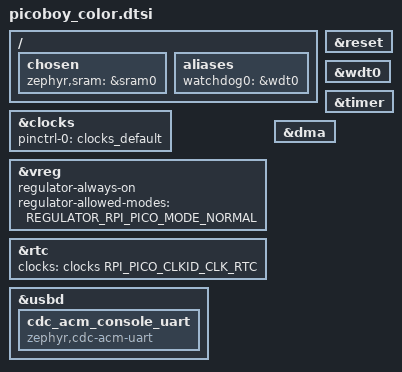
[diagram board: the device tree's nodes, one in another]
/*
 * Copyright (c) 2023-2025 TiaC Systems
 * SPDX-License-Identifier: Apache-2.0
 */

#include <mem.h>
#include <freq.h>
#include <raspberrypi/rpi_pico/rp2040.dtsi>
#include <zephyr/dt-bindings/regulator/rpi_pico.h>

#include "pbc-pinctrl.dtsi"

/ {
	chosen {
		zephyr,sram = &sram0;
	};

	aliases {
		watchdog0 = &wdt0;
	};
};

&clocks {
	pinctrl-0 = <&clocks_default>;
	pinctrl-names = "default";
};

&reset {
	status = "okay";
};

&vreg {
	regulator-always-on;
	regulator-allowed-modes = <REGULATOR_RPI_PICO_MODE_NORMAL>;
};

&wdt0 {
	status = "okay";
};

&rtc {
	clocks = <&clocks RPI_PICO_CLKID_CLK_RTC>;
	status = "okay";
};

&timer {
	status = "okay";
};

&dma {
	status = "okay";
};

zephyr_udc0: &usbd {
	status = "okay";

	cdc_acm_console_uart: cdc_acm_console_uart {
		compatible = "zephyr,cdc-acm-uart";
	};
};
